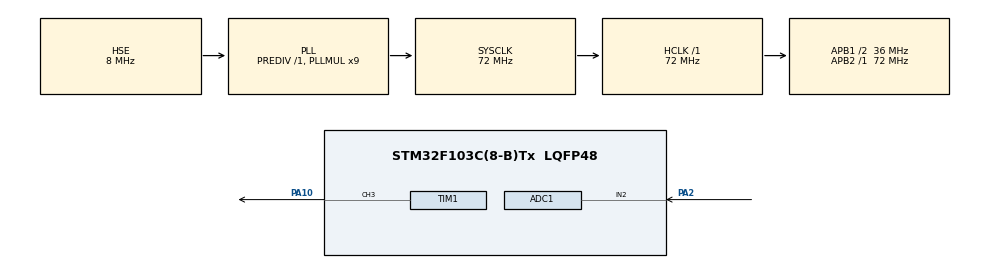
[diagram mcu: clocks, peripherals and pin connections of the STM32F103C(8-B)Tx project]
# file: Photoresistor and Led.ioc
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ADC1.Channel-1\#ChannelRegularConversion=ADC_CHANNEL_2
ADC1.ContinuousConvMode=ENABLE
ADC1.NbrOfConversionFlag=1
ADC1.Rank-1\#ChannelRegularConversion=1
ADC1.SamplingTime-1\#ChannelRegularConversion=ADC_SAMPLETIME_41CYCLES_5
ADC1.master=1
Mcu.Family=STM32F1
Mcu.Name=STM32F103C(8-B)Tx
Mcu.Package=LQFP48
NVIC.ADC1_2_IRQn=true\:0\:0\:false\:false\:true\:true\:true\:true
NVIC.PriorityGroup=NVIC_PRIORITYGROUP_4
PA10.Signal=S_TIM1_CH3
PA13.Mode=Serial_Wire
PA13.Signal=SYS_JTMS-SWDIO
PA14.Mode=Serial_Wire
PA14.Signal=SYS_JTCK-SWCLK
PA2.Signal=ADCx_IN2
PD0-OSC_IN.Mode=HSE-External-Oscillator
PD0-OSC_IN.Signal=RCC_OSC_IN
PD1-OSC_OUT.Mode=HSE-External-Oscillator
PD1-OSC_OUT.Signal=RCC_OSC_OUT
ProjectManager.HeapSize=0x200
ProjectManager.StackSize=0x400
ProjectManager.TargetToolchain=STM32CubeIDE
RCC.ADCPresc=RCC_ADCPCLK2_DIV6
RCC.AHBFreq_Value=72000000
RCC.APB1CLKDivider=RCC_HCLK_DIV2
RCC.APB1Freq_Value=36000000
RCC.APB1TimFreq_Value=72000000
RCC.APB2Freq_Value=72000000
RCC.APB2TimFreq_Value=72000000
RCC.HCLKFreq_Value=72000000
RCC.PLLMUL=RCC_PLL_MUL9
RCC.PLLSourceVirtual=RCC_PLLSOURCE_HSE
RCC.SYSCLKFreq_VALUE=72000000
RCC.SYSCLKSource=RCC_SYSCLKSOURCE_PLLCLK
RCC.USBFreq_Value=72000000
SH.ADCx_IN2.0=ADC1_IN2,IN2
SH.S_TIM1_CH3.0=TIM1_CH3,PWM Generation3 CH3
TIM1.AutoReloadPreload=TIM_AUTORELOAD_PRELOAD_ENABLE
TIM1.Channel-PWM\ Generation3\ CH3=TIM_CHANNEL_3
TIM1.Period=500
TIM1.Prescaler=1000
TIM1.Pulse-PWM\ Generation3\ CH3=250
VP_TIM1_VS_ClockSourceINT.Mode=Internal
board=custom

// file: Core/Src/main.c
/* USER CODE BEGIN Header */
/**
  ******************************************************************************
  * @file           : main.c
  * @brief          : Main program body
  ******************************************************************************
  * @attention
  *
  * Copyright (c) 2023 STMicroelectronics.
  * All rights reserved.
  *
  * This software is licensed under terms that can be found in the LICENSE file
  * in the root directory of this software component.
  * If no LICENSE file comes with this software, it is provided AS-IS.
  *
  ******************************************************************************
  */
/* USER CODE END Header */
#include "main.h"
#include "adc.h"
#include "tim.h"
#include "gpio.h"

/* USER CODE BEGIN Includes */
uint32_t adc = 0;
/* USER CODE END Includes */

void SystemClock_Config(void);
/* USER CODE BEGIN PFP */
//void setPWM(uint16_t pwm_value);
/* USER CODE END PFP */

/* USER CODE BEGIN 0 */
void HAL_ADC_ConvCpltCallback(ADC_HandleTypeDef *hadc)
{
	if (hadc->Instance == ADC1)
	{
		adc = HAL_ADC_GetValue(&hadc1);
	}
}
/* USER CODE END 0 */

int main(void)
{

  /* MCU Configuration--------------------------------------------------------*/

  /* Reset of all peripherals, Initializes the Flash interface and the Systick. */
  HAL_Init();

  /* Configure the system clock */
  SystemClock_Config();

  /* Initialize all configured peripherals */
  MX_GPIO_Init();
  MX_ADC1_Init();
  MX_TIM1_Init();
  /* USER CODE BEGIN 2 */
  HAL_TIM_PWM_Start(&htim1, TIM_CHANNEL_3);
  HAL_ADCEx_Calibration_Start(&hadc1);
  HAL_ADC_Start_IT(&hadc1);
  /* USER CODE END 2 */

  /* Infinite loop */
  while (1)
  {
	  __HAL_TIM_SET_COMPARE(&htim1, TIM_CHANNEL_3, 1500 - (adc/2.2));
  }
}

void SystemClock_Config(void)
{
  RCC_OscInitTypeDef RCC_OscInitStruct = {0};
  RCC_ClkInitTypeDef RCC_ClkInitStruct = {0};
  RCC_PeriphCLKInitTypeDef PeriphClkInit = {0};

  /** Initializes the RCC Oscillators according to the specified parameters
  * in the RCC_OscInitTypeDef structure.
  */
  RCC_OscInitStruct.OscillatorType = RCC_OSCILLATORTYPE_HSE;
  RCC_OscInitStruct.HSEState = RCC_HSE_ON;
  RCC_OscInitStruct.HSEPredivValue = RCC_HSE_PREDIV_DIV1;
  RCC_OscInitStruct.HSIState = RCC_HSI_ON;
  RCC_OscInitStruct.PLL.PLLState = RCC_PLL_ON;
  RCC_OscInitStruct.PLL.PLLSource = RCC_PLLSOURCE_HSE;
  RCC_OscInitStruct.PLL.PLLMUL = RCC_PLL_MUL9;
  if (HAL_RCC_OscConfig(&RCC_OscInitStruct) != HAL_OK)
  {
    Error_Handler();
  }

  /** Initializes the CPU, AHB and APB buses clocks
  */
  RCC_ClkInitStruct.ClockType = RCC_CLOCKTYPE_HCLK|RCC_CLOCKTYPE_SYSCLK
                              |RCC_CLOCKTYPE_PCLK1|RCC_CLOCKTYPE_PCLK2;
  RCC_ClkInitStruct.SYSCLKSource = RCC_SYSCLKSOURCE_PLLCLK;
  RCC_ClkInitStruct.AHBCLKDivider = RCC_SYSCLK_DIV1;
  RCC_ClkInitStruct.APB1CLKDivider = RCC_HCLK_DIV2;
  RCC_ClkInitStruct.APB2CLKDivider = RCC_HCLK_DIV1;

  if (HAL_RCC_ClockConfig(&RCC_ClkInitStruct, FLASH_LATENCY_2) != HAL_OK)
  {
    Error_Handler();
  }
  PeriphClkInit.PeriphClockSelection = RCC_PERIPHCLK_ADC;
  PeriphClkInit.AdcClockSelection = RCC_ADCPCLK2_DIV6;
  if (HAL_RCCEx_PeriphCLKConfig(&PeriphClkInit) != HAL_OK)
  {
    Error_Handler();
  }
}

void Error_Handler(void)
{
  __disable_irq();
  while (1)
  {
  }
}
